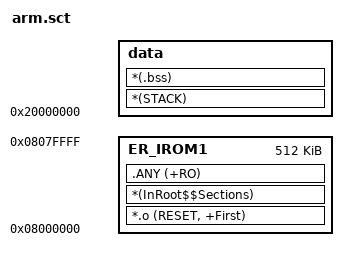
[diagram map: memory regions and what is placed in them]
; *************************************************************
; *** Scatter-Loading Description File generated by uVision ***
; *************************************************************

LR_IROM1 0x08000000 0x00080000  {    ; load region size_region
  ER_IROM1 0x08000000 0x00080000  {  ; load address = execution address
   *.o (RESET, +First)
   *(InRoot$$Sections)
   .ANY (+RO)
  }
  data 0x20000000 { ; .data
   *(.data)
  }
  __initcall + 0 { ; initcall
   ;*(initcall0_init)
   ;*(initcall1_init)
   ;*(initcall2_init)
   *(initcall3_init)
   ;*(initcall4_init)
   ;*(initcall5_init)
   ;*(initcall6_init)
   ;*(initcall7_init)
  }
  bss + 0 { ; .bss
   *(STACK)
   ;*(HEAP)     ; 使用MicroLIB时，不能定义HEAP
   *(.bss)
  }
}

